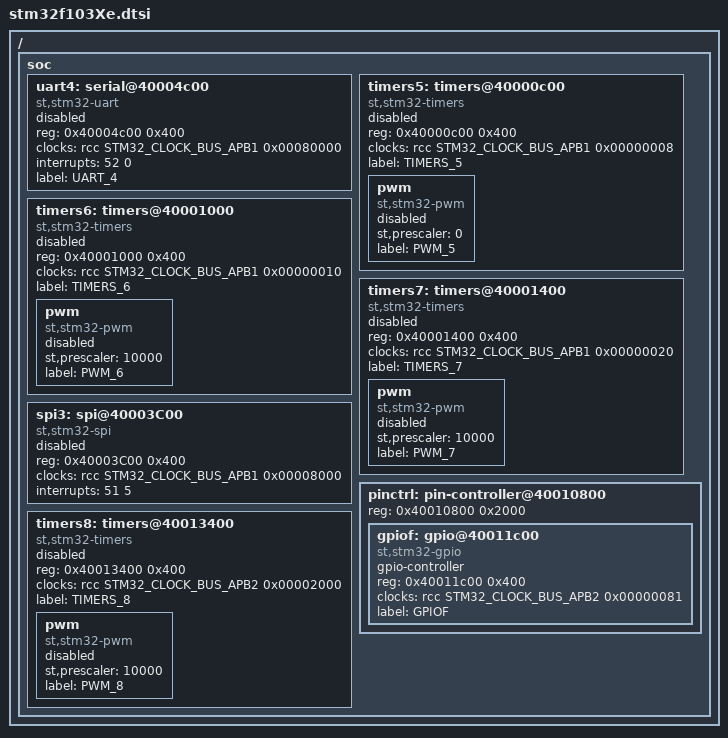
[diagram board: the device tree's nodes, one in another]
/*
 * Copyright (c) 2017 I-SENSE group of ICCS
 *
 * SoC device tree include for STM32F103xE SoCs
 * where 'x' is replaced for specific SoCs like {R,V,Z}
 *
 * SPDX-License-Identifier: Apache-2.0
 */

#include <st/stm32f103Xb.dtsi>

/ {
	soc {
		uart4: serial@40004c00 {
			compatible = "st,stm32-uart";
			reg = <0x40004c00 0x400>;
			clocks = <&rcc STM32_CLOCK_BUS_APB1 0x00080000>;
			interrupts = <52 0>;
			status = "disabled";
			label = "UART_4";
		};

		timers5: timers@40000c00 {
			compatible = "st,stm32-timers";
			reg = <0x40000c00 0x400>;
			clocks = <&rcc STM32_CLOCK_BUS_APB1 0x00000008>;
			status = "disabled";
			label = "TIMERS_5";

			pwm {
				compatible = "st,stm32-pwm";
				status = "disabled";
				st,prescaler = <0>;
				label = "PWM_5";
			};
		};

		timers6: timers@40001000 {
			compatible = "st,stm32-timers";
			reg = <0x40001000 0x400>;
			clocks = <&rcc STM32_CLOCK_BUS_APB1 0x00000010>;
			status = "disabled";
			label = "TIMERS_6";

			pwm {
				compatible = "st,stm32-pwm";
				status = "disabled";
				st,prescaler = <10000>;
				label = "PWM_6";
			};
		};

		timers7: timers@40001400 {
			compatible = "st,stm32-timers";
			reg = <0x40001400 0x400>;
			clocks = <&rcc STM32_CLOCK_BUS_APB1 0x00000020>;
			status = "disabled";
			label = "TIMERS_7";

			pwm {
				compatible = "st,stm32-pwm";
				status = "disabled";
				st,prescaler = <10000>;
				label = "PWM_7";
			};
		};

		spi3: spi@40003C00 {
			compatible = "st,stm32-spi";
			#address-cells = <1>;
			#size-cells = <0>;
			reg = <0x40003C00 0x400>;
			clocks = <&rcc STM32_CLOCK_BUS_APB1 0x00008000>;
			interrupts = <51 5>;
			status = "disabled";
		};

		pinctrl: pin-controller@40010800 {
			reg = <0x40010800 0x2000>;

			gpiof: gpio@40011c00 {
				compatible = "st,stm32-gpio";
				gpio-controller;
				#gpio-cells = <2>;
				reg = <0x40011c00 0x400>;
				clocks = <&rcc STM32_CLOCK_BUS_APB2 0x00000081>;
				label = "GPIOF";
			};
		};

		timers8: timers@40013400 {
			compatible = "st,stm32-timers";
			reg = <0x40013400 0x400>;
			clocks = <&rcc STM32_CLOCK_BUS_APB2 0x00002000>;
			status = "disabled";
			label = "TIMERS_8";

			pwm {
				compatible = "st,stm32-pwm";
				status = "disabled";
				st,prescaler = <10000>;
				label = "PWM_8";
			};
		};
	};
};
